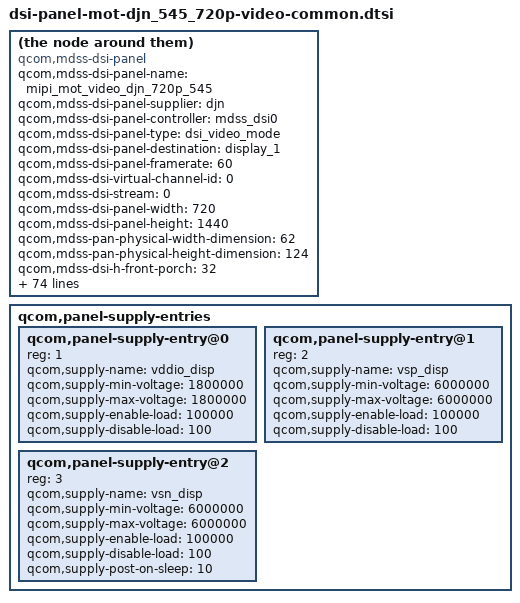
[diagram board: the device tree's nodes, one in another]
/* Copyright (c) 2018, The Linux Foundation. All rights reserved.
 *
 * This program is free software; you can redistribute it and/or modify
 * it under the terms of the GNU General Public License version 2 and
 * only version 2 as published by the Free Software Foundation.
 *
 * This program is distributed in the hope that it will be useful,
 * but WITHOUT ANY WARRANTY; without even the implied warranty of
 * MERCHANTABILITY or FITNESS FOR A PARTICULAR PURPOSE.  See the
 * GNU General Public License for more details.
 */

compatible = "qcom,mdss-dsi-panel";
qcom,mdss-dsi-panel-name = "mipi_mot_video_djn_720p_545";
qcom,mdss-dsi-panel-supplier = "djn";
qcom,mdss-dsi-panel-controller = <&mdss_dsi0>;
qcom,mdss-dsi-panel-type = "dsi_video_mode";
qcom,mdss-dsi-panel-destination = "display_1";
qcom,mdss-dsi-panel-framerate = <60>;
qcom,mdss-dsi-virtual-channel-id = <0>;
qcom,mdss-dsi-stream = <0>;
qcom,mdss-dsi-panel-width = <720>;
qcom,mdss-dsi-panel-height = <1440>;
qcom,mdss-pan-physical-width-dimension = <62>;
qcom,mdss-pan-physical-height-dimension = <124>;
qcom,mdss-dsi-h-front-porch = <32>;
qcom,mdss-dsi-h-back-porch = <280>;
qcom,mdss-dsi-h-pulse-width = <12>;
qcom,mdss-dsi-h-sync-skew = <0>;
qcom,mdss-dsi-v-back-porch = <12>;
qcom,mdss-dsi-v-front-porch = <10>;
qcom,mdss-dsi-v-pulse-width = <4>;
qcom,mdss-dsi-h-left-border = <0>;
qcom,mdss-dsi-h-right-border = <0>;
qcom,mdss-dsi-v-top-border = <0>;
qcom,mdss-dsi-v-bottom-border = <0>;
qcom,mdss-dsi-bpp = <24>;
qcom,mdss-dsi-underflow-color = <0xff>;
qcom,mdss-dsi-border-color = <0>;
qcom,mdss-dsi-on-command = [
	39 01 00 00 00 00 04 B9 FF 83 94
	39 01 00 00 00 00 02 35 00
	15 01 00 00 00 00 02 51 D0
	39 01 00 00 00 00 0A CA 24 24 24 23 23 23 22 20 20
	39 01 00 00 00 00 1B CE 40 40 40 40 40 40 40 40 40 40 40 40 40 40 40 40 40 40 40 40 40 40 40 40 40 40
	39 01 00 00 00 00 3B E0 00 09 13 19 1C 20 24 21 46 55 64 65 6D 7F 82 85 92 96 8F 9A A8 52 51 54 56 58 5B 5D 5C 00 09 13 19 1C 20 24 21 46 55 64 65 6D 7F 82 85 92 96 8F 9A A8 52 51 54 56 58 5B 5D 5C
	15 01 00 00 00 00 02 55 11
	15 01 00 00 00 00 02 53 24
	39 01 00 00 78 00 02 11 00
	39 01 00 00 32 00 02 29 00
	];
qcom,mdss-dsi-off-command = [
	05 01 00 00 32 00 02 28 00
	05 01 00 00 78 00 02 10 00
];


qcom,mdss-dsi-on-command-state = "dsi_lp_mode";
qcom,mdss-dsi-off-command-state = "dsi_hs_mode";

qcom,mdss-dsi-cabc-ui-command = [
39 01 00 00 00 00 0A CA 24 24 24 23 23 23 22 20 20
39 01 00 00 00 00 1B CE 40 40 40 40 40 40 40 40 40 40 40 40 40 40 40 40 40 40 40 40 40 40 40 40 40 40
39 01 00 00 00 00 3B E0 00 09 13 19 1C 20 24 21 46 55 64 65 6D 7F 82 85 92 96 8F 9A A8 52 51 54 56 58 5B 5D 5C 00 09 13 19 1C 20 24 21 46 55 64 65 6D 7F 82 85 92 96 8F 9A A8 52 51 54 56 58 5B 5D 5C
15 01 00 00 00 00 02 55 01];
qcom,mdss-dsi-cabc-ui-command-state = "dsi_hs_mode";
qcom,mdss-dsi-cabc-mv-command = [
39 01 00 00 00 00 0A CA 40 3C 38 34 2A 28 25 21 21
39 01 00 00 00 00 1B CE 40 40 40 40 40 40 40 40 40 40 40 40 40 40 40 40 40 40 40 40 40 40 40 40 40 40
39 01 00 00 00 00 3B E0 00 07 12 14 12 15 1B 18 31 3D 4C 43 49 5C 69 72 80 85 80 8C 99 4B 49 4D 51 54 59 5D 5C 00 07 12 14 12 15 1B 18 31 3D 4C 43 49 5C 69 72 80 85 80 8C 99 4B 49 4D 51 54 59 5D 5C
15 01 00 00 00 00 02 55 03];
qcom,mdss-dsi-cabc-mv-command-state = "dsi_hs_mode";
qcom,mdss-dsi-cabc-dis-command = [
39 01 00 00 00 00 3B E0 00 09 13 19 1C 20 24 21 46 55 64 65 6D 7F 82 85 92 96 8F 9A A8 52 51 54 56 58 5B 5D 5C 00 09 13 19 1C 20 24 21 46 55 64 65 6D 7F 82 85 92 96 8F 9A A8 52 51 54 56 58 5B 5D 5C
15 01 00 00 00 00 02 55 00];
qcom,mdss-dsi-cabc-dis-command-state = "dsi_hs_mode";
qcom,mdss-dsi-hbm-on-command = [39 01 00 00 00 00 02 51 FF];
qcom,mdss-dsi-hbm-on-command-state = "dsi_hs_mode";
qcom,mdss-dsi-hbm-off-command = [39 01 00 00 00 00 02 51 D0];
qcom,mdss-dsi-hbm-off-command-state = "dsi_hs_mode";
qcom,mdss-dsi-hbm-type = "lcd-dcs-wled";

qcom,mdss-dsi-h-sync-pulse = <1>;
qcom,mdss-dsi-traffic-mode = "burst_mode";
qcom,mdss-dsi-lane-map = "lane_map_0123";
qcom,mdss-dsi-bllp-eof-power-mode;
qcom,mdss-dsi-bllp-power-mode;
//qcom,mdss-dsi-hfp-power-mode;
//qcom,mdss-dsi-lp11-init;
qcom,mdss-dsi-lane-0-state;
qcom,mdss-dsi-lane-1-state;
qcom,mdss-dsi-lane-2-state;
qcom,mdss-dsi-lane-3-state;
qcom,mdss-dsi-panel-timings = [98 22 16 00 4A 4E 1A 26 1A 03 04 00];
qcom,mdss-dsi-t-clk-post = <0x04>;
qcom,mdss-dsi-t-clk-pre = <0x1e>;
qcom,mdss-dsi-bl-min-level = <1>;
qcom,mdss-dsi-bl-max-level = <4095>;
qcom,mdss-dsi-dma-trigger = "trigger_sw";
qcom,mdss-dsi-mdp-trigger = "none";
qcom,mdss-dsi-bl-pmic-control-type = "bl_ctrl_wled";
qcom,mdss-dsi-reset-sequence = <1 20>, <0 2>, <1 50>;
qcom,mdss-dsi-tx-eot-append;
qcom,mdss-dsi-init-delay-us = <50000>;
qcom,mdss-dsi-no-panel-on-read-support;
qcom,cont-splash-enabled;
qcom,esd-check-enabled;
qcom,mdss-dsi-panel-status-command = [06 01 00 01 00 00 01 09];
qcom,mdss-dsi-panel-status-command-state = "dsi_lp_mode";
qcom,mdss-dsi-panel-status-check-mode = "reg_read";
qcom,mdss-dsi-panel-status-read-length = <3>;
qcom,mdss-dsi-panel-status-value =
	<0x80 0x73 0x06>;

qcom,panel-supply-entries {
	#address-cells = <1>;
	#size-cells = <0>;
	qcom,panel-supply-entry@0 {
		reg = <1>;
		qcom,supply-name = "vddio_disp";
		qcom,supply-min-voltage = <1800000>;
		qcom,supply-max-voltage = <1800000>;
		qcom,supply-enable-load = <100000>;
		qcom,supply-disable-load = <100>;
	};
	qcom,panel-supply-entry@1 {
		reg = <2>;
		qcom,supply-name = "vsp_disp";
		qcom,supply-min-voltage = <6000000>;
		qcom,supply-max-voltage = <6000000>;
		qcom,supply-enable-load = <100000>;
		qcom,supply-disable-load = <100>;
	};
	qcom,panel-supply-entry@2 {
		reg = <3>;
		qcom,supply-name = "vsn_disp";
		qcom,supply-min-voltage = <6000000>;
		qcom,supply-max-voltage = <6000000>;
		qcom,supply-enable-load = <100000>;
		qcom,supply-disable-load = <100>;
		qcom,supply-post-on-sleep = <10>;
	};
};
